# ATmega128RFA1 device description
Architecture: AVR8; Family: megaAVR
Registers are 8-bit, access not given, no defined reset value unless marked. A register's access mark holds for its fields unless they carry their own. Offsets are from the block's base; [hi:lo] are bit positions; {n}, {i} and the like mark numbered series.

## USART0 — USART
Instances: USART0 0x00
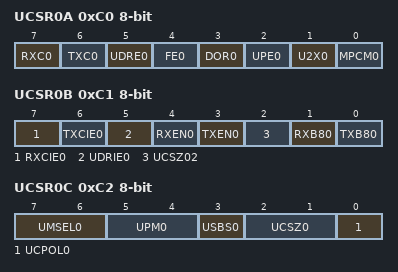
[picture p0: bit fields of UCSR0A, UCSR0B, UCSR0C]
0xC0 UCSR0A — USART0 Control and Status Register A
  [7] RXC0 — USART Receive Complete
  [6] TXC0 — USART Transmit Complete
  [5] UDRE0 — USART Data Register Empty
  [4] FE0 — Frame Error
  [3] DOR0 — Data OverRun
  [2] UPE0 — USART Parity Error
  [1] U2X0 — Double the USART Transmission Speed
  [0] MPCM0 — Multi-processor Communication Mode
0xC1 UCSR0B — USART0 Control and Status Register B
  [7] RXCIE0 — RX Complete Interrupt Enable
  [6] TXCIE0 — TX Complete Interrupt Enable
  [5] UDRIE0 — USART Data Register Empty Interrupt Enable
  [4] RXEN0 — Receiver Enable
  [3] TXEN0 — Transmitter Enable
  [2] UCSZ02 — Character Size
  [1] RXB80 — Receive Data Bit 8
  [0] TXB80 — Transmit Data Bit 8
0xC2 UCSR0C — USART0 Control and Status Register C
  [7:6] UMSEL0 — USART Mode Select
    0=Asynchronous USART; 1=Synchronous USART; 3=Master SPI (MSPIM)
  [5:4] UPM0 — Parity Mode
    0=Disabled; 2=Enabled, Even Parity; 3=Enabled, Odd Parity
  [3] USBS0 — Stop Bit Select
    0=1-bit; 1=2-bit
  [2:1] UCSZ0 — Character Size
    {v}={v+5}-bit (v=0..3); 7=9-bit
  [0] UCPOL0 — Clock Polarity
    0=Rising XCKn Edge (Transmitted Data Changed), Falling XCKn Edge (Received Data Sampled); 1=Falling XCKn Edge (Transmitted Data Changed), Rising XCKn Edge (Received Data Sampled)
0xC4 UBRR0 16-bit — USART0 Baud Rate Register Bytes
0xC6 UDR0 — USART0 I/O Data Register

## USART1 — USART
Instances: USART1 0x00
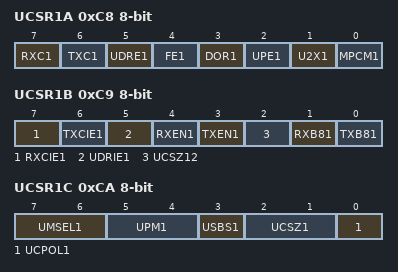
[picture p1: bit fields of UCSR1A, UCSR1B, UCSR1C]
0xC8 UCSR1A — USART1 Control and Status Register A
  [7] RXC1 — USART Receive Complete
  [6] TXC1 — USART Transmit Complete
  [5] UDRE1 — USART Data Register Empty
  [4] FE1 — Frame Error
  [3] DOR1 — Data OverRun
  [2] UPE1 — USART Parity Error
  [1] U2X1 — Double the USART Transmission Speed
  [0] MPCM1 — Multi-processor Communication Mode
0xC9 UCSR1B — USART1 Control and Status Register B
  [7] RXCIE1 — RX Complete Interrupt Enable
  [6] TXCIE1 — TX Complete Interrupt Enable
  [5] UDRIE1 — USART Data Register Empty Interrupt Enable
  [4] RXEN1 — Receiver Enable
  [3] TXEN1 — Transmitter Enable
  [2] UCSZ12 — Character Size
  [1] RXB81 — Receive Data Bit 8
  [0] TXB81 — Transmit Data Bit 8
0xCA UCSR1C — USART1 Control and Status Register C
  [7:6] UMSEL1 — USART Mode Select
    0=Asynchronous USART; 1=Synchronous USART; 3=Master SPI (MSPIM)
  [5:4] UPM1 — Parity Mode
    0=Disabled; 2=Enabled, Even Parity; 3=Enabled, Odd Parity
  [3] USBS1 — Stop Bit Select
    0=1-bit; 1=2-bit
  [2:1] UCSZ1 — Character Size
    {v}={v+5}-bit (v=0..3); 7=9-bit
  [0] UCPOL1 — Clock Polarity
    0=Rising XCKn Edge (Transmitted Data Changed), Falling XCKn Edge (Received Data Sampled); 1=Falling XCKn Edge (Transmitted Data Changed), Rising XCKn Edge (Received Data Sampled)
0xCC UBRR1 16-bit — USART1 Baud Rate Register Bytes
0xCE UDR1 — USART1 I/O Data Register

## TWI — Two Wire Serial Interface
Instances: TWI 0x00
0xB8 TWBR — TWI Bit Rate Register
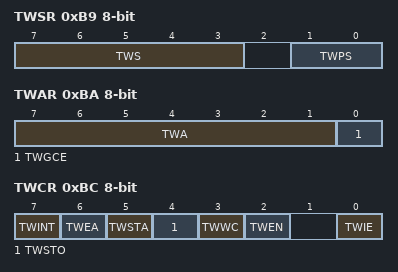
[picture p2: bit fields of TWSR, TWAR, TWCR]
0xB9 TWSR — TWI Status Register
  [7:3] TWS (bit 3 of the value upward) — TWI Status
    0=Bus error due to illegal START or STOP condition; 8=A START condition has been transmitted; 16=A repeated START condition has been transmitted; 24=SLA+W has been transmitted; ACK has been received; 32=SLA+W has been transmitted; NOT ACK has been received; 40=Data byte has been transmitted; ACK has been received; 48=Data byte has been transmitted; NOT ACK has been received; 56=Arbitration lost in SLA+W or data bytes (Transmitter); Arbitration lost in SLA+R or NOT ACK bit (Receiver); 64=SLA+R has been transmitted; ACK has been received; 72=SLA+R has been transmitted; NOT ACK has been received; 80=Data byte has been received; ACK has been returned; 88=Data byte has been received; NOT ACK has been returned; 96=Own SLA+W has been received; ACK has been returned; 104=Arbitration lost in SLA+R/W as Master; own SLA+W has been received; ACK has been returned; 112=General call address has been received; ACK has been returned; 120=Arbitration lost in SLA+R/W as Master; general call address has been received; ACK has been returned; 128=Previously addressed with own SLA+W; data has been received; ACK has been returned; 136=Previously addressed with own SLA+W; data has been received; NOT ACK has been returned; 144=Previously addressed with general call; data has been received; ACK has been returned; 152=Previously addressed with general call; data has been received; NOT ACK has been returned; 160=A STOP condition or repeated START condition has been received while still addressed as Slave; 168=Own SLA+R has been received; ACK has been returned; 176=Arbitration lost in SLA+R/W as Master; own SLA+R has been received; ACK has been returned; 184=Data byte in TWDR has been transmitted; ACK has been received; 192=Data byte in TWDR has been transmitted; NO ACK has been received; 200=Last data byte in TWDR has been transmitted (TWEA = 0); ACK has been received; 248=No relevant state information available; TWINT = 0
  [1:0] TWPS — TWI Prescaler Bits
    0=1; 1=4; 2=16; 3=64
0xBA TWAR — TWI (Slave) Address Register
  [7:1] TWA — TWI (Slave) Address
  [0] TWGCE — TWI General Call Recognition Enable Bit
0xBB TWDR — TWI Data Register
0xBC TWCR — TWI Control Register
  [7] TWINT — TWI Interrupt Flag
  [6] TWEA — TWI Enable Acknowledge Bit
  [5] TWSTA — TWI START Condition Bit
  [4] TWSTO — TWI STOP Condition Bit
  [3] TWWC — TWI Write Collision Flag
  [2] TWEN — TWI Enable Bit
  [0] TWIE — TWI Interrupt Enable
0xBD TWAMR — TWI (Slave) Address Mask Register
  [7:1] TWAM — TWI Address Mask
